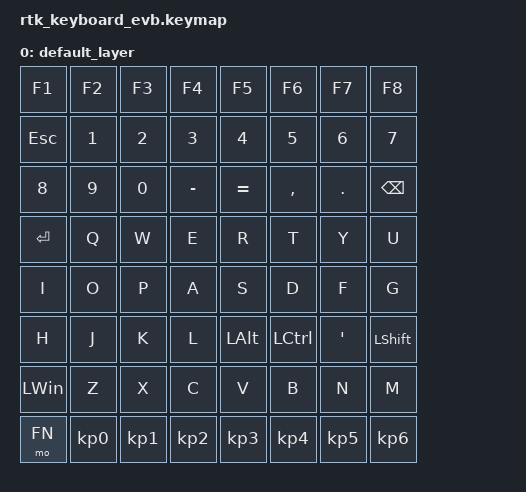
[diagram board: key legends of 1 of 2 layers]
/*
 * Copyright (c) 2023 The ZMK Contributors
 *
 * SPDX-License-Identifier: MIT
 */

#include <behaviors.dtsi>
#include <dt-bindings/zmk/bt.h>
#include <dt-bindings/zmk/keys.h>
#include <dt-bindings/zmk/rgb.h>

#define DEFAULT 0
#define FN      1

/ {
    keymap {
        compatible = "zmk,keymap";

        default_layer {
            bindings = <
            &kp F1     &kp F2    &kp F3     &kp F4    &kp F5     &kp F6     &kp F7        &kp F8
            &kp ESC    &kp N1     &kp N2    &kp N3    &kp N4     &kp N5     &kp N6        &kp N7
            &kp N8     &kp N9     &kp N0    &kp MINUS &kp EQUAL  &kp COMMA  &kp DOT       &kp BACKSPACE
            &kp ENTER  &kp Q      &kp W     &kp E      &kp R     &kp T      &kp Y         &kp U
            &kp I      &kp O      &kp P     &kp A      &kp S     &kp D      &kp F         &kp G
            &kp H      &kp J      &kp K     &kp L      &kp LALT  &kp LCTRL  &kp SQT       &kp LSHFT
            &kp LWIN   &kp Z      &kp X     &kp C      &kp V     &kp B      &kp N         &kp M
            &mo FN     &kp KP_N0  &kp KP_N1 &kp KP_N2  &kp KP_N3 &kp KP_N4  &kp KP_N5     &kp KP_N6
            >;  
        };

        fn_layer {
            bindings = <
            &kp C_MUTE  &kp C_VOL_DN  &kp C_VOL_UP  &kp C_BRI_DEC &kp C_BRI_INC &kp C_AC_SEARCH &kp C_AC_DESKTOP_SHOW_ALL_WINDOWS &kp C_PLAY_PAUSE
            &bt BT_CLR
            >;
        };
        
    };
};

